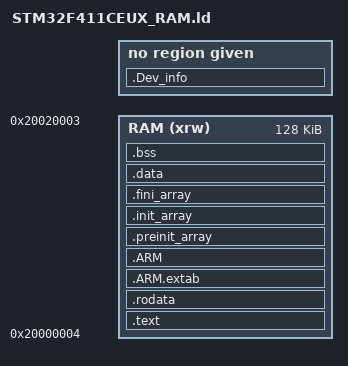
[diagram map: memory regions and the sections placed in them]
/**
 ******************************************************************************
 * @file      LinkerScript.ld
 * @author    Auto-generated by STM32CubeIDE
 * @brief     Linker script for STM32F411CEUx Device from STM32F4 series
 *                      512Kbytes ROM
 *                      128Kbytes RAM
 *
 *            Set heap size, stack size and stack location according
 *            to application requirements.
 *
 *            Set memory bank area and size if external memory is used
 ******************************************************************************
 * @attention
 *
 * <h2><center>&copy; Copyright (c) 2020 STMicroelectronics.
 * All rights reserved.</center></h2>
 *
 * This software component is licensed by ST under BSD 3-Clause license,
 * the "License"; You may not use this file except in compliance with the
 * License. You may obtain a copy of the License at:
 *                        opensource.org/licenses/BSD-3-Clause
 *
 ******************************************************************************
 */

/* Entry Point */
ENTRY(Init)

/* Generate 2 segment for loader code and device info */
PHDRS {Loader PT_LOAD ; SgInfo PT_LOAD ; }

/* Memories definition */
MEMORY
{
  RAM    (xrw)    : ORIGIN = 0x20000004,   LENGTH = 128K
}

/* Sections */
SECTIONS
{
  /* The program code and other data into "RAM" Ram type memory */
  .text :
  {
    . = ALIGN(4);
    *(.text)           /* .text sections (code) */
    *(.text*)          /* .text* sections (code) */
    *(.glue_7)         /* glue arm to thumb code */
    *(.glue_7t)        /* glue thumb to arm code */
    *(.eh_frame)

    KEEP (*(.init))
    KEEP (*(.fini))

    . = ALIGN(4);
    _etext = .;        /* define a global symbols at end of code */
  } >RAM :Loader
  
  .Dev_info :
  {
	KEEP(Sources/0_Loader_Files/Dev_Inf.o ( .rodata ))
  } :SgInfo

  /* Constant data into "RAM" Ram type memory */
  .rodata :
  {
    . = ALIGN(4);
    *(.rodata)         /* .rodata sections (constants, strings, etc.) */
    *(.rodata*)        /* .rodata* sections (constants, strings, etc.) */
    . = ALIGN(4);
  } >RAM :Loader

  .ARM.extab   : { 
    . = ALIGN(4);
    *(.ARM.extab* .gnu.linkonce.armextab.*)
    . = ALIGN(4);
  } >RAM :Loader
  
  .ARM : {
    . = ALIGN(4);
    __exidx_start = .;
    *(.ARM.exidx*)
    __exidx_end = .;
    . = ALIGN(4);
  } >RAM :Loader

  .preinit_array     :
  {
    . = ALIGN(4);
    PROVIDE_HIDDEN (__preinit_array_start = .);
    KEEP (*(.preinit_array*))
    PROVIDE_HIDDEN (__preinit_array_end = .);
    . = ALIGN(4);
  } >RAM :Loader
  
  .init_array :
  {
    . = ALIGN(4);
    PROVIDE_HIDDEN (__init_array_start = .);
    KEEP (*(SORT(.init_array.*)))
    KEEP (*(.init_array*))
    PROVIDE_HIDDEN (__init_array_end = .);
    . = ALIGN(4);
  } >RAM :Loader
  
  .fini_array :
  {
    . = ALIGN(4);
    PROVIDE_HIDDEN (__fini_array_start = .);
    KEEP (*(SORT(.fini_array.*)))
    KEEP (*(.fini_array*))
    PROVIDE_HIDDEN (__fini_array_end = .);
    . = ALIGN(4);
  } >RAM :Loader

  /* Used by the startup to initialize data */
  _sidata = LOADADDR(.data);

  /* Initialized data sections into "RAM" Ram type memory */
  .data : 
  {
    . = ALIGN(4);
    _sdata = .;        /* create a global symbol at data start */
    *(.data)           /* .data sections */
    *(.data*)          /* .data* sections */

    . = ALIGN(4);
    _edata = .;        /* define a global symbol at data end */
    
  } >RAM :Loader

  /* Uninitialized data section into "RAM" Ram type memory */
  . = ALIGN(4);
  .bss :
  {
    /* This is used by the startup in order to initialize the .bss section */
    _sbss = .;         /* define a global symbol at bss start */
    __bss_start__ = _sbss;
    *(.bss)
    *(.bss*)
    *(COMMON)

    . = ALIGN(4);
    _ebss = .;         /* define a global symbol at bss end */
    __bss_end__ = _ebss;
  } >RAM :Loader

  /* Remove information from the compiler libraries */
  /DISCARD/ :
  {
    libc.a ( * )
    libm.a ( * )
    libgcc.a ( * )
  }

  .ARM.attributes 0 : { *(.ARM.attributes) }
}
